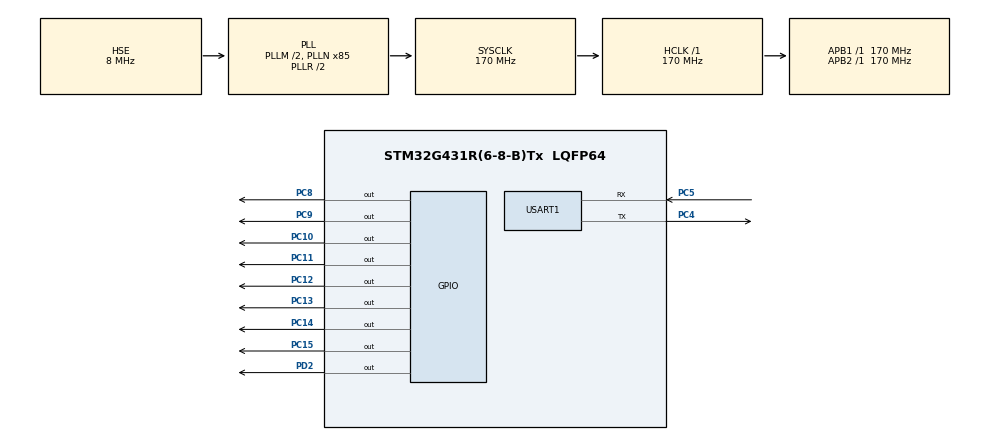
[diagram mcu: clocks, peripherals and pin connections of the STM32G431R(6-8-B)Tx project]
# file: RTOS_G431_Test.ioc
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Dma.Request0=USART1_RX
Dma.USART1_RX.0.Direction=DMA_PERIPH_TO_MEMORY
Dma.USART1_RX.0.EventEnable=DISABLE
Dma.USART1_RX.0.Instance=DMA1_Channel1
Dma.USART1_RX.0.MemDataAlignment=DMA_MDATAALIGN_BYTE
Dma.USART1_RX.0.MemInc=DMA_MINC_ENABLE
Dma.USART1_RX.0.Mode=DMA_CIRCULAR
Dma.USART1_RX.0.PeriphDataAlignment=DMA_PDATAALIGN_BYTE
Dma.USART1_RX.0.PeriphInc=DMA_PINC_DISABLE
Dma.USART1_RX.0.Polarity=HAL_DMAMUX_REQ_GEN_RISING
Dma.USART1_RX.0.Priority=DMA_PRIORITY_LOW
Dma.USART1_RX.0.RequestNumber=1
Dma.USART1_RX.0.SignalID=NONE
Dma.USART1_RX.0.SyncEnable=DISABLE
Dma.USART1_RX.0.SyncPolarity=HAL_DMAMUX_SYNC_NO_EVENT
Dma.USART1_RX.0.SyncRequestNumber=1
Dma.USART1_RX.0.SyncSignalID=NONE
FREERTOS.Tasks01=defaultTask,24,128,StartDefaultTask,Default,NULL,Dynamic,NULL,NULL;blink,8,128,Tsk_blink,As external,NULL,Dynamic,NULL,NULL
FREERTOS.Timers01=tim_blink,Tim_blink,osTimerPeriodic,As external,NULL,Dynamic,NULL
FREERTOS.configENABLE_FPU=1
Mcu.Family=STM32G4
Mcu.Name=STM32G431R(6-8-B)Tx
Mcu.Package=LQFP64
NVIC.DMA1_Channel1_IRQn=true\:5\:0\:false\:false\:true\:true\:false\:true\:true
NVIC.PriorityGroup=NVIC_PRIORITYGROUP_4
NVIC.TIM1_UP_TIM16_IRQn=true\:5\:0\:false\:false\:true\:true\:true\:true\:true
NVIC.TIM6_DAC_IRQn=true\:15\:0\:false\:false\:true\:false\:false\:true\:true
NVIC.TimeBase=TIM6_DAC_IRQn
NVIC.TimeBaseIP=TIM6
NVIC.USART1_IRQn=true\:5\:0\:false\:false\:true\:true\:true\:true\:true
PA13.Mode=Serial_Wire
PA13.Signal=SYS_JTMS-SWDIO
PA14.Mode=Serial_Wire
PA14.Signal=SYS_JTCK-SWCLK
PC10.GPIO_ModeDefaultOutputPP=GPIO_MODE_OUTPUT_PP
PC10.GPIO_PuPd=GPIO_PULLUP
PC10.GPIO_Speed=GPIO_SPEED_FREQ_LOW
PC10.PinState=GPIO_PIN_SET
PC10.Signal=GPIO_Output
PC11.GPIO_ModeDefaultOutputPP=GPIO_MODE_OUTPUT_PP
PC11.GPIO_PuPd=GPIO_PULLUP
PC11.GPIO_Speed=GPIO_SPEED_FREQ_LOW
PC11.PinState=GPIO_PIN_SET
PC11.Signal=GPIO_Output
PC12.GPIO_ModeDefaultOutputPP=GPIO_MODE_OUTPUT_PP
PC12.GPIO_PuPd=GPIO_PULLUP
PC12.GPIO_Speed=GPIO_SPEED_FREQ_LOW
PC12.PinState=GPIO_PIN_SET
PC12.Signal=GPIO_Output
PC13.GPIO_ModeDefaultOutputPP=GPIO_MODE_OUTPUT_PP
PC13.GPIO_PuPd=GPIO_PULLUP
PC13.GPIO_Speed=GPIO_SPEED_FREQ_LOW
PC13.PinState=GPIO_PIN_SET
PC13.Signal=GPIO_Output
PC14-OSC32_IN.GPIO_ModeDefaultOutputPP=GPIO_MODE_OUTPUT_PP
PC14-OSC32_IN.GPIO_PuPd=GPIO_PULLUP
PC14-OSC32_IN.GPIO_Speed=GPIO_SPEED_FREQ_LOW
PC14-OSC32_IN.PinState=GPIO_PIN_SET
PC14-OSC32_IN.Signal=GPIO_Output
PC15-OSC32_OUT.GPIO_ModeDefaultOutputPP=GPIO_MODE_OUTPUT_PP
PC15-OSC32_OUT.GPIO_PuPd=GPIO_PULLUP
PC15-OSC32_OUT.GPIO_Speed=GPIO_SPEED_FREQ_LOW
PC15-OSC32_OUT.PinState=GPIO_PIN_SET
PC15-OSC32_OUT.Signal=GPIO_Output
PC4.Mode=Asynchronous
PC4.Signal=USART1_TX
PC5.Mode=Asynchronous
PC5.Signal=USART1_RX
PC8.GPIO_ModeDefaultOutputPP=GPIO_MODE_OUTPUT_PP
PC8.GPIO_PuPd=GPIO_PULLUP
PC8.GPIO_Speed=GPIO_SPEED_FREQ_LOW
PC8.PinState=GPIO_PIN_SET
PC8.Signal=GPIO_Output
PC9.GPIO_ModeDefaultOutputPP=GPIO_MODE_OUTPUT_PP
PC9.GPIO_PuPd=GPIO_PULLUP
PC9.GPIO_Speed=GPIO_SPEED_FREQ_LOW
PC9.PinState=GPIO_PIN_SET
PC9.Signal=GPIO_Output
PD2.GPIO_PuPd=GPIO_PULLDOWN
PD2.Signal=GPIO_Output
PF0-OSC_IN.Mode=HSE-External-Oscillator
PF0-OSC_IN.Signal=RCC_OSC_IN
PF1-OSC_OUT.Mode=HSE-External-Oscillator
PF1-OSC_OUT.Signal=RCC_OSC_OUT
ProjectManager.HeapSize=0x200
ProjectManager.StackSize=0x400
ProjectManager.TargetToolchain=MDK-ARM V5.32
RCC.ADC12Freq_Value=170000000
RCC.AHBFreq_Value=170000000
RCC.APB1Freq_Value=170000000
RCC.APB1TimFreq_Value=170000000
RCC.APB2Freq_Value=170000000
RCC.APB2TimFreq_Value=170000000
RCC.CortexFreq_Value=170000000
RCC.EXTERNAL_CLOCK_VALUE=12288000
RCC.EnbaleCSS=true
RCC.HCLKFreq_Value=170000000
RCC.HSE_VALUE=8000000
RCC.HSI48_VALUE=48000000
RCC.HSI_VALUE=16000000
RCC.LSE_VALUE=32768
RCC.PLLM=RCC_PLLM_DIV2
RCC.PLLN=85
RCC.PLLSourceVirtual=RCC_PLLSOURCE_HSE
RCC.PWR_Regulator_Voltage_Scale=PWR_REGULATOR_VOLTAGE_SCALE1_BOOST
RCC.SYSCLKFreq_VALUE=170000000
RCC.SYSCLKSource=RCC_SYSCLKSOURCE_PLLCLK
RCC.USBFreq_Value=170000000
RCC.VCOOutputFreq_Value=340000000
TIM1.AutoReloadPreload=TIM_AUTORELOAD_PRELOAD_ENABLE
TIM1.PeriodNoDither=9999
TIM1.Prescaler=16999
USART1.VirtualMode-Asynchronous=VM_ASYNC
VP_FREERTOS_VS_CMSIS_V2.Mode=CMSIS_V2
VP_SYS_VS_DBSignals.Mode=DisableDeadBatterySignals
VP_SYS_VS_tim6.Mode=TIM6
VP_TIM1_VS_ClockSourceINT.Mode=Internal
board=custom

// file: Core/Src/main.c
/* USER CODE BEGIN Header */
/**
  ******************************************************************************
  * @file           : main.c
  * @brief          : Main program body
  ******************************************************************************
  * @attention
  *
  * Copyright (c) 2023 STMicroelectronics.
  * All rights reserved.
  *
  * This software is licensed under terms that can be found in the LICENSE file
  * in the root directory of this software component.
  * If no LICENSE file comes with this software, it is provided AS-IS.
  *
  ******************************************************************************
  */
/* USER CODE END Header */
#include "main.h"
#include "cmsis_os.h"
#include "dma.h"
#include "tim.h"
#include "usart.h"
#include "gpio.h"

void SystemClock_Config(void);
void MX_FREERTOS_Init(void);

/* USER CODE BEGIN 0 */
void Tsk_blink() {
	while(1) {
		HAL_GPIO_WritePin(GPIOC, 0xFE00, 1);
		HAL_GPIO_TogglePin(GPIOC,0x0100);
		HAL_GPIO_WritePin(GPIOD, 0x0002, 1);
		HAL_GPIO_WritePin(GPIOD, 0x0002, 0);
		vTaskDelay(500);
	}
}
/* USER CODE END 0 */

int main(void)
{

  /* MCU Configuration--------------------------------------------------------*/

  /* Reset of all peripherals, Initializes the Flash interface and the Systick. */
  HAL_Init();

  /* Configure the system clock */
  SystemClock_Config();

  /* Initialize all configured peripherals */
  MX_GPIO_Init();
  MX_DMA_Init();
  MX_USART1_UART_Init();
  MX_TIM1_Init();

  /* Init scheduler */
  osKernelInitialize();  /* Call init function for freertos objects (in freertos.c) */
  MX_FREERTOS_Init();

  /* Start scheduler */
  osKernelStart();

  /* We should never get here as control is now taken by the scheduler */
  /* Infinite loop */
  while (1)
  {

  }
}

void SystemClock_Config(void)
{
  RCC_OscInitTypeDef RCC_OscInitStruct = {0};
  RCC_ClkInitTypeDef RCC_ClkInitStruct = {0};

  /** Configure the main internal regulator output voltage
  */
  HAL_PWREx_ControlVoltageScaling(PWR_REGULATOR_VOLTAGE_SCALE1_BOOST);

  /** Initializes the RCC Oscillators according to the specified parameters
  * in the RCC_OscInitTypeDef structure.
  */
  RCC_OscInitStruct.OscillatorType = RCC_OSCILLATORTYPE_HSE;
  RCC_OscInitStruct.HSEState = RCC_HSE_ON;
  RCC_OscInitStruct.PLL.PLLState = RCC_PLL_ON;
  RCC_OscInitStruct.PLL.PLLSource = RCC_PLLSOURCE_HSE;
  RCC_OscInitStruct.PLL.PLLM = RCC_PLLM_DIV2;
  RCC_OscInitStruct.PLL.PLLN = 85;
  RCC_OscInitStruct.PLL.PLLP = RCC_PLLP_DIV2;
  RCC_OscInitStruct.PLL.PLLQ = RCC_PLLQ_DIV2;
  RCC_OscInitStruct.PLL.PLLR = RCC_PLLR_DIV2;
  if (HAL_RCC_OscConfig(&RCC_OscInitStruct) != HAL_OK)
  {
    Error_Handler();
  }

  /** Initializes the CPU, AHB and APB buses clocks
  */
  RCC_ClkInitStruct.ClockType = RCC_CLOCKTYPE_HCLK|RCC_CLOCKTYPE_SYSCLK
                              |RCC_CLOCKTYPE_PCLK1|RCC_CLOCKTYPE_PCLK2;
  RCC_ClkInitStruct.SYSCLKSource = RCC_SYSCLKSOURCE_PLLCLK;
  RCC_ClkInitStruct.AHBCLKDivider = RCC_SYSCLK_DIV1;
  RCC_ClkInitStruct.APB1CLKDivider = RCC_HCLK_DIV1;
  RCC_ClkInitStruct.APB2CLKDivider = RCC_HCLK_DIV1;

  if (HAL_RCC_ClockConfig(&RCC_ClkInitStruct, FLASH_LATENCY_4) != HAL_OK)
  {
    Error_Handler();
  }

  /** Enables the Clock Security System
  */
  HAL_RCC_EnableCSS();
}

void HAL_TIM_PeriodElapsedCallback(TIM_HandleTypeDef *htim)
{
  if (htim->Instance == TIM6) {
    HAL_IncTick();
  }
}

void Error_Handler(void)
{
  __disable_irq();
  while (1)
  {
  }
}

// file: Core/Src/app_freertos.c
/* USER CODE BEGIN Header */
/**
  ******************************************************************************
  * File Name          : app_freertos.c
  * Description        : Code for freertos applications
  ******************************************************************************
  * @attention
  *
  * Copyright (c) 2023 STMicroelectronics.
  * All rights reserved.
  *
  * This software is licensed under terms that can be found in the LICENSE file
  * in the root directory of this software component.
  * If no LICENSE file comes with this software, it is provided AS-IS.
  *
  ******************************************************************************
  */
/* USER CODE END Header */

#include "FreeRTOS.h"
#include "task.h"
#include "main.h"
#include "cmsis_os.h"

/* Definitions for defaultTask */
osThreadId_t defaultTaskHandle;
const osThreadAttr_t defaultTask_attributes = {
  .name = "defaultTask",
  .priority = (osPriority_t) osPriorityNormal,
  .stack_size = 128 * 4
};
/* Definitions for blink */
osThreadId_t blinkHandle;
const osThreadAttr_t blink_attributes = {
  .name = "blink",
  .priority = (osPriority_t) osPriorityLow,
  .stack_size = 128 * 4
};
/* Definitions for tim_blink */
osTimerId_t tim_blinkHandle;
const osTimerAttr_t tim_blink_attributes = {
  .name = "tim_blink"
};

void StartDefaultTask(void *argument);
extern void Tsk_blink(void *argument);
extern void Tim_blink(void *argument);

void MX_FREERTOS_Init(void); /* (MISRA C 2004 rule 8.1) */

void MX_FREERTOS_Init(void) {

  /* Create the timer(s) */
  /* creation of tim_blink */
  tim_blinkHandle = osTimerNew(Tim_blink, osTimerPeriodic, NULL, &tim_blink_attributes);

  /* Create the thread(s) */
  /* creation of defaultTask */
  defaultTaskHandle = osThreadNew(StartDefaultTask, NULL, &defaultTask_attributes);

  /* creation of blink */
  blinkHandle = osThreadNew(Tsk_blink, NULL, &blink_attributes);

  /* USER CODE BEGIN RTOS_EVENTS */
  /* add events, ... */
  vTaskStartScheduler();
  /* USER CODE END RTOS_EVENTS */

}

void StartDefaultTask(void *argument)
{
  for(;;)
  {
    osDelay(1);
  }
}
